# STM32N655xx register map
File version: 1.0
Registers are 32-bit, read-write, reset 0x0 unless marked. A register's access mark holds for its fields unless they carry their own. Offsets are from the block's base; [hi:lo] are bit positions; lines under a group give offsets from that group; {n}, {i} and the like mark numbered series.

## ADC1 — Analog to Digital Converter (ADC)
Base 0x40022000
Same registers: ADC2 0x40022100
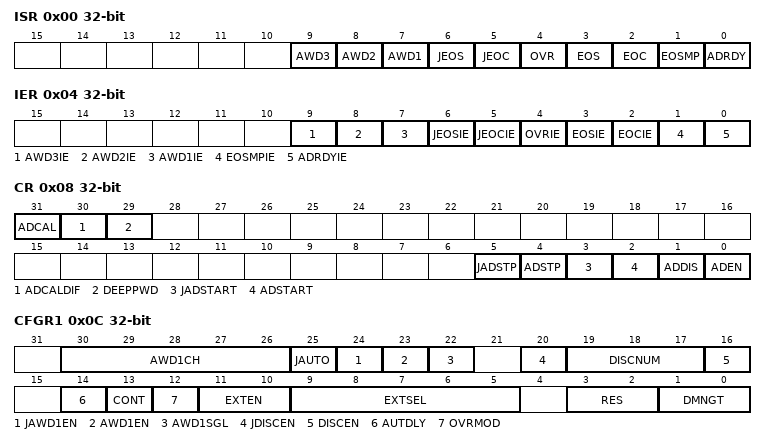
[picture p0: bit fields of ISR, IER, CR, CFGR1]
0x00 ISR — ADC interrupt and status register
  [9] AWD3 — ADC analog watchdog 3 flag
  [8] AWD2 — ADC analog watchdog 2 flag
  [7] AWD1 — ADC analog watchdog 1 flag
  [6] JEOS — ADC group injected end of sequence conversions flag
  [5] JEOC — ADC group injected end of unitary conversion flag
  [4] OVR — ADC group regular overrun flag
  [3] EOS — ADC group regular end of sequence conversions flag
  [2] EOC — ADC group regular end of unitary conversion flag
  [1] EOSMP — ADC group regular end of sampling flag
  [0] ADRDY — ADC ready flag
0x04 IER — ADC interrupt enable register
  [9] AWD3IE — ADC analog watchdog 3 interrupt
  [8] AWD2IE — ADC analog watchdog 2 interrupt
  [7] AWD1IE — ADC analog watchdog 1 interrupt
  [6] JEOSIE — ADC group injected end of sequence conversions interrupt
  [5] JEOCIE — ADC group injected end of unitary conversion interrupt
  [4] OVRIE — ADC group regular overrun interrupt
  [3] EOSIE — ADC group regular end of sequence conversions interrupt
  [2] EOCIE — ADC group regular end of unitary conversion interrupt
  [1] EOSMPIE — ADC group regular end of sampling interrupt
  [0] ADRDYIE — ADC ready interrupt
0x08 CR — ADC control register
  [31] ADCAL — ADC calibration
  [30] ADCALDIF — ADC differential mode for calibration
  [29] DEEPPWD — ADC deep power down enable
  [5] JADSTP — ADC group injected conversion stop
  [4] ADSTP — ADC group regular conversion stop
  [3] JADSTART — ADC group injected conversion start
  [2] ADSTART — ADC group regular conversion start
  [1] ADDIS — ADC disable
  [0] ADEN — ADC enable
0x0C CFGR1 — ADC configuration register 1
  [30:26] AWD1CH — ADC analog watchdog 1 monitored channel selection
  [25] JAUTO — ADC group injected automatic trigger mode
  [24] JAWD1EN — ADC analog watchdog 1 enable on scope ADC group injected
  [23] AWD1EN — ADC analog watchdog 1 enable on scope ADC group regular
  [22] AWD1SGL — ADC analog watchdog 1 monitoring a single channel or all channels
  [20] JDISCEN — ADC group injected sequencer discontinuous mode
  [19:17] DISCNUM — ADC group regular sequencer discontinuous number of ranks
  [16] DISCEN — ADC group regular sequencer discontinuous mode
  [14] AUTDLY — ADC low power auto wait
  [13] CONT — ADC group regular continuous conversion mode
  [12] OVRMOD — ADC group regular overrun configuration
  [11:10] EXTEN — ADC group regular external trigger polarity
  [9:5] EXTSEL — ADC group regular external trigger source
  [3:2] RES — ADC data resolution
  [1:0] DMNGT — ADC data management configuration
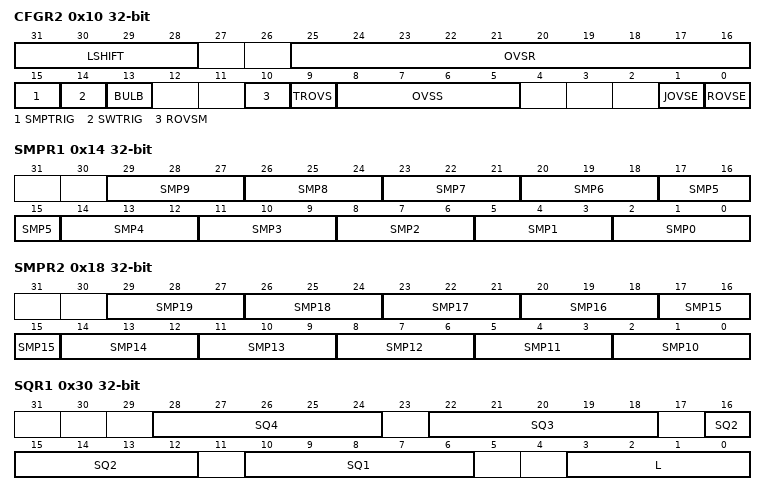
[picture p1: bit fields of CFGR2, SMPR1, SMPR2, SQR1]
0x10 CFGR2 — ADC configuration register 2
  [31:28] LSHIFT — ADC left shift factor
  [25:16] OVSR — ADC oversampling ratio
  [15] SMPTRIG — ADC sampling time control trigger mode
  [14] SWTRIG — ADC software trigger bit for sampling time control trigger mode
  [13] BULB — ADC bulb sampling mode
  [10] ROVSM — ADC oversampling mode managing interlaced conversions of ADC group regular and group injected
  [9] TROVS — ADC oversampling discontinuous mode (triggered mode) for ADC group regular
  [8:5] OVSS — ADC oversampling shift
  [1] JOVSE — ADC oversampler enable on scope ADC group injected
  [0] ROVSE — ADC oversampler enable on scope ADC group regular
0x14 SMPR1 — ADC sample time register 1
  [3n+2:3n] SMP{n} (n=0..9) — ADC channel {n} sampling time selection
0x18 SMPR2 — ADC sample time register 2
  [29:27] SMP19 — ADC Channel 19 Sampling time selection
  [3n-28:3n-30] SMP{n} (n=10..18) — ADC channel {n} sampling time selection
0x1C PCSEL — ADC channel preselection register
  [19:0] PCSEL — ADC channel preselection
0x30 SQR1 — ADC regular sequence register 1
  [6n+4:6n] SQ{n} (n=1..4) — ADC group regular sequencer rank {n}
  [3:0] L — ADC group regular sequencer scan length
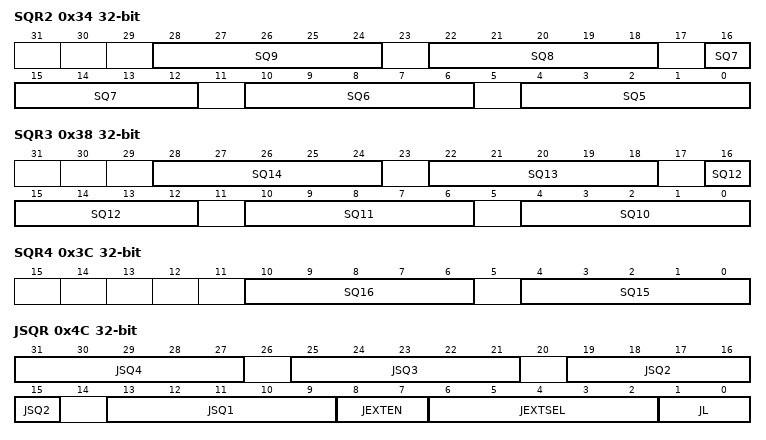
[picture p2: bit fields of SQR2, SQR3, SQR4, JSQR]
0x34 SQR2 — ADC regular sequence register 2
  [6n-26:6n-30] SQ{n} (n=5..9) — ADC group regular sequencer rank {n}
0x38 SQR3 — ADC regular sequence register 3
  [6n-56:6n-60] SQ{n} (n=10..14) — ADC group regular sequencer rank {n}
0x3C SQR4 — ADC regular sequence register 4
  [10:6] SQ16 — ADC group regular sequencer rank 16
  [4:0] SQ15 — ADC group regular sequencer rank 15
0x40 DR — ADC regular data register
  [31:0] RDATA — ADC group regular conversion data
0x4C JSQR — ADC injected sequence register
  [6n+7:6n+3] JSQ{n} (n=1..4) — ADC group injected sequencer rank {n}
  [8:7] JEXTEN — ADC group injected external trigger polarity
  [6:2] JEXTSEL — ADC group injected external trigger source
  [1:0] JL — ADC group injected sequencer scan length
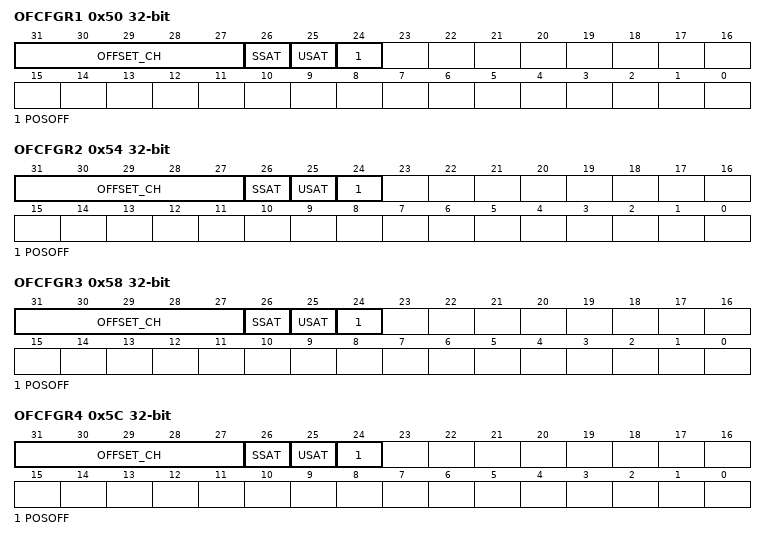
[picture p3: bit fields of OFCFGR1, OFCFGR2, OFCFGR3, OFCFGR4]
0x50 OFCFGR1 — ADC
  [31:27] OFFSET_CH — ADC offset instance 1 channel selection
  [26] SSAT — ADC offset instance 1 signed satuaration enable
  [25] USAT — ADC offset instance 1 unsigned saturation value
  [24] POSOFF — ADC offset instance 1 positive offset enable
0x54 OFCFGR2 — ADC
  [31:27] OFFSET_CH — ADC offset instance 2 channel selection
  [26] SSAT — ADC offset instance 2 signed satuaration enable
  [25] USAT — ADC offset instance 2 unsigned saturation value
  [24] POSOFF — ADC offset instance 2 positive offset enable
0x58 OFCFGR3 — ADC
  [31:27] OFFSET_CH — ADC offset instance 3 channel selection for the data offset
  [26] SSAT — ADC offset instance 3 signed satuaration enable
  [25] USAT — ADC offset instance 3 unsigned saturation value
  [24] POSOFF — ADC offset instance 3 positive offset enable
0x5C OFCFGR4 — ADC
  [31:27] OFFSET_CH — ADC offset instance 4 channel selection for the data offset
  [26] SSAT — ADC offset instance 4 signed satuaration enable
  [25] USAT — ADC offset instance 4 unsigned saturation value
  [24] POSOFF — ADC offset instance 4 positive offset enable
{0x5C+4i} OFR{i} (i=1..4) — ADC
  [21:0] OFFSET — ADC offset instance {i} offset level
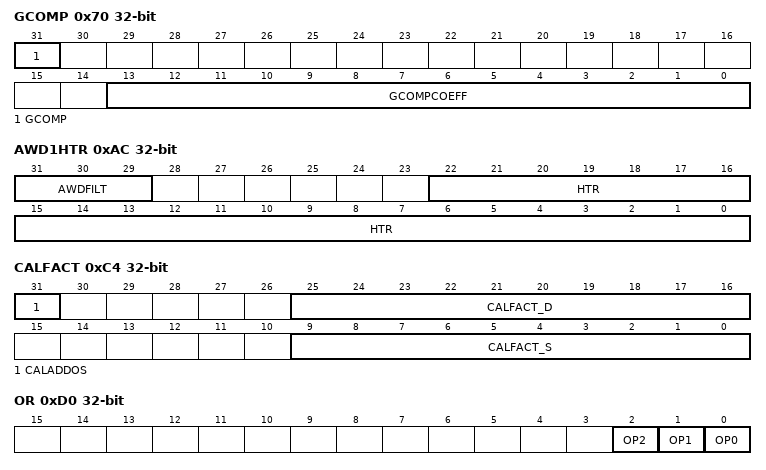
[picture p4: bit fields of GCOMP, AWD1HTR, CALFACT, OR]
0x70 GCOMP — ADC gain compensation register
  [31] GCOMP — Gain compensation mode
  [13:0] GCOMPCOEFF — Gain compensation coefficient
{0x7C+4i} JDR{i} (i=1..4) — ADC injected data register {i}
  [31:0] JDATA — ADC group injected sequencer rank {i} conversion data
0xA0 AWD2CR — ADC analog watchdog 2 configuration register
  [19:0] AWD2CH — ADC analog watchdog 2 monitored channel selection
0xA4 AWD3CR — ADC analog watchdog 3 configuration register
  [19:0] AWD3CH — ADC analog watchdog 3 monitored channel selection
{0xA0+8i} AWD{i}LTR (i=1..3) — ADC analog watchdog {i} low threshold register
  [22:0] LTR — ADC analog watchdog {i} threshold low
0xAC AWD1HTR — ADC analog watchdog 1 high threshold register
  [31:29] AWDFILT — ADC analog watchdog 1 filtering
  [22:0] HTR — ADC analog watchdog 1 threshold high
0xB4 AWD2HTR — ADC analog watchdog 2 high threshold register
  [22:0] HTR — ADC analog watchdog 2 threshold high
0xBC AWD3HTR — ADC analog watchdog 3 high threshold register
  [22:0] HTR — ADC analog watchdog 3 threshold high
0xC0 DIFSEL — ADC differential mode selection register
  [19:0] DIFSEL — ADC channel differential or single-ended mode selection
0xC4 CALFACT — ADC calibration factors
  [31] CALADDOS — ADC calibration additional offset mode
  [25:16] CALFACT_D — ADC calibration factor in differential mode
  [9:0] CALFACT_S — ADC calibration factor in single-ended mode
0xD0 OR — ADC option register
  [2] OP2 — ADC internal path to VDDCORE
  [1] OP1 — ADC internal bandgap
  [0] OP0 — ADC internal reference voltage buffer
